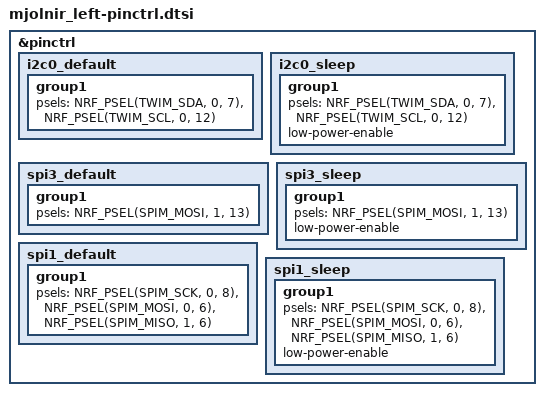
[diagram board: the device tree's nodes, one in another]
&pinctrl {
    i2c0_default: i2c0_default {
            group1 {
                    psels = <NRF_PSEL(TWIM_SDA, 0, 7)>,
                            <NRF_PSEL(TWIM_SCL, 0, 12)>;
            };
    };

    i2c0_sleep: i2c0_sleep {
            group1 {
                    psels = <NRF_PSEL(TWIM_SDA, 0, 7)>,
                            <NRF_PSEL(TWIM_SCL, 0, 12)>;
                    low-power-enable;
            };
    };

    spi3_default: spi3_default {
        group1 {
            psels = <NRF_PSEL(SPIM_MOSI, 1, 13)>;
        };
    };

    spi3_sleep: spi3_sleep {
        group1 {
            psels = <NRF_PSEL(SPIM_MOSI, 1, 13)>;
            low-power-enable;
        };
    };

    spi1_default: spi1_default {
        group1 {
            psels = <NRF_PSEL(SPIM_SCK, 0, 8)>,
                <NRF_PSEL(SPIM_MOSI, 0, 6)>,
                <NRF_PSEL(SPIM_MISO, 1, 6)>;
        };
    };

    spi1_sleep: spi1_sleep {
        group1 {
            psels = <NRF_PSEL(SPIM_SCK, 0, 8)>,
                <NRF_PSEL(SPIM_MOSI, 0, 6)>,
                <NRF_PSEL(SPIM_MISO, 1, 6)>;
            low-power-enable;
        };
    };

};
